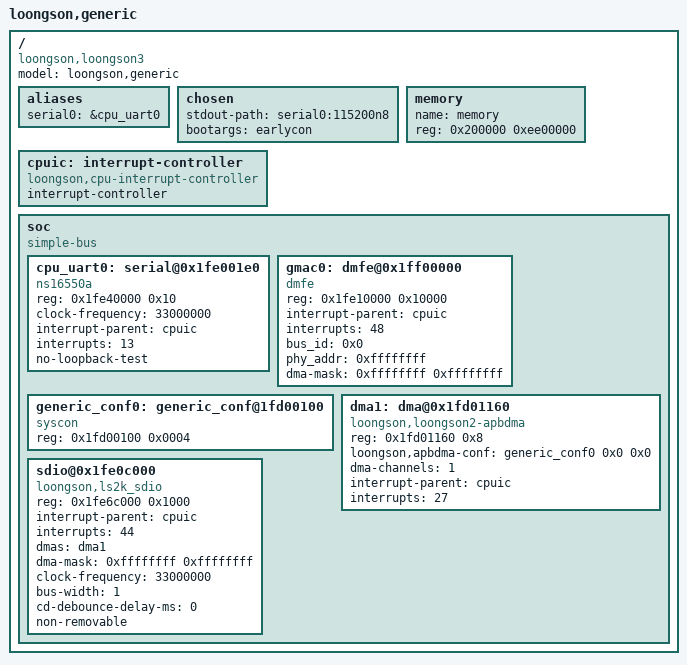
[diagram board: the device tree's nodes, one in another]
// SPDX-License-Identifier: GPL-2.0
/dts-v1/;

/ {
	model = "loongson,generic";
	compatible = "loongson,loongson3";
	#address-cells = <1>;
	#size-cells = <1>;

	aliases {
		serial0 = &cpu_uart0;
	};

	chosen {
		stdout-path = "serial0:115200n8";
		bootargs = "earlycon";
	};

	memory {
		name = "memory";
		device_type = "memory";
		reg = <0x200000 0xee00000>;
	};

	cpuic: interrupt-controller {
		compatible = "loongson,cpu-interrupt-controller";
		interrupt-controller;
		#interrupt-cells = <1>;
	};

	soc {
		compatible = "simple-bus";
		#address-cells = <1>;
		#size-cells = <1>;
		ranges = <0x10000000 0x10000000 0x10000000>;

		cpu_uart0: serial@0x1fe001e0 {
			compatible = "ns16550a";
			reg = <0x1fe40000  0x10>;
			clock-frequency = <33000000>;
			interrupt-parent = <&cpuic>;
			interrupts = <13>;
			no-loopback-test;
		};

		gmac0: dmfe@0x1ff00000 {
			compatible = "dmfe";
			reg = <0x1fe10000 0x10000>;
			interrupt-parent = <&cpuic>;
			interrupts = <48>;
			interrupt-names = "macirq";
			bus_id = <0x0>;
			phy_addr = <0xffffffff>;
			dma-mask = <0xffffffff 0xffffffff>;
		};

		generic_conf0: generic_conf@1fd00100 {
			compatible = "syscon";
			reg = <0x1fd00100 0x0004>;
		};

		dma1: dma@0x1fd01160 {
			compatible = "loongson,loongson2-apbdma";
			reg = <0x1fd01160 0x8>;
			loongson,apbdma-conf = <&generic_conf0 0x0 0x0>;
			#dma-cells = <0>;
			dma-channels = <1>;
			interrupt-parent = <&cpuic>;
			interrupts = <27>;			/* todo */
		};

		sdio@0x1fe0c000 {
			#address-cells = <1>;

			compatible = "loongson,ls2k_sdio";
			reg = <0x1fe6c000 0x1000>;
			interrupt-parent = <&cpuic>;
			interrupts = <44>;
			interrupt-names = "bx_mci_irq";

			dmas = <&dma1>;
			dma-names = "sdio_rw";
			dma-mask = <0xffffffff 0xffffffff>;
			clock-frequency = <33000000>;
			bus-width = <1>;
			cd-debounce-delay-ms = <0>;
			non-removable;
		};
#if 0
		ahci@0x1fe30000 {
			compatible = "snps,spear-ahci";
			reg = <0x1fe30000 0x10000>;
			interrupt-parent = <&cpuic>;
			interrupts = <4>;
			dma-mask = <0x0 0xffffffff>;
		};

		nand@0x1fe78000 {
			#address-cells = <1>;
			#size-cells = <1>;
			compatible = "ls1a-nand";
			reg = <0x00000000 0x4000
			 0x00000000 0x0>;
	 		interrupt-parent = <&cpuic>;
			interrupts = <4>;
			interrupt-names = "nand_irq";

			number-of-parts = <0x2>;
			partition@0 {
				label = "kernel_partition";
				reg = <0x0000000 0x01400000>;
			};

			partition@0x01400000 {
				label = "os_partition";
				reg = <0x01400000 0x0>;
			};
		};
#endif
	};
};

